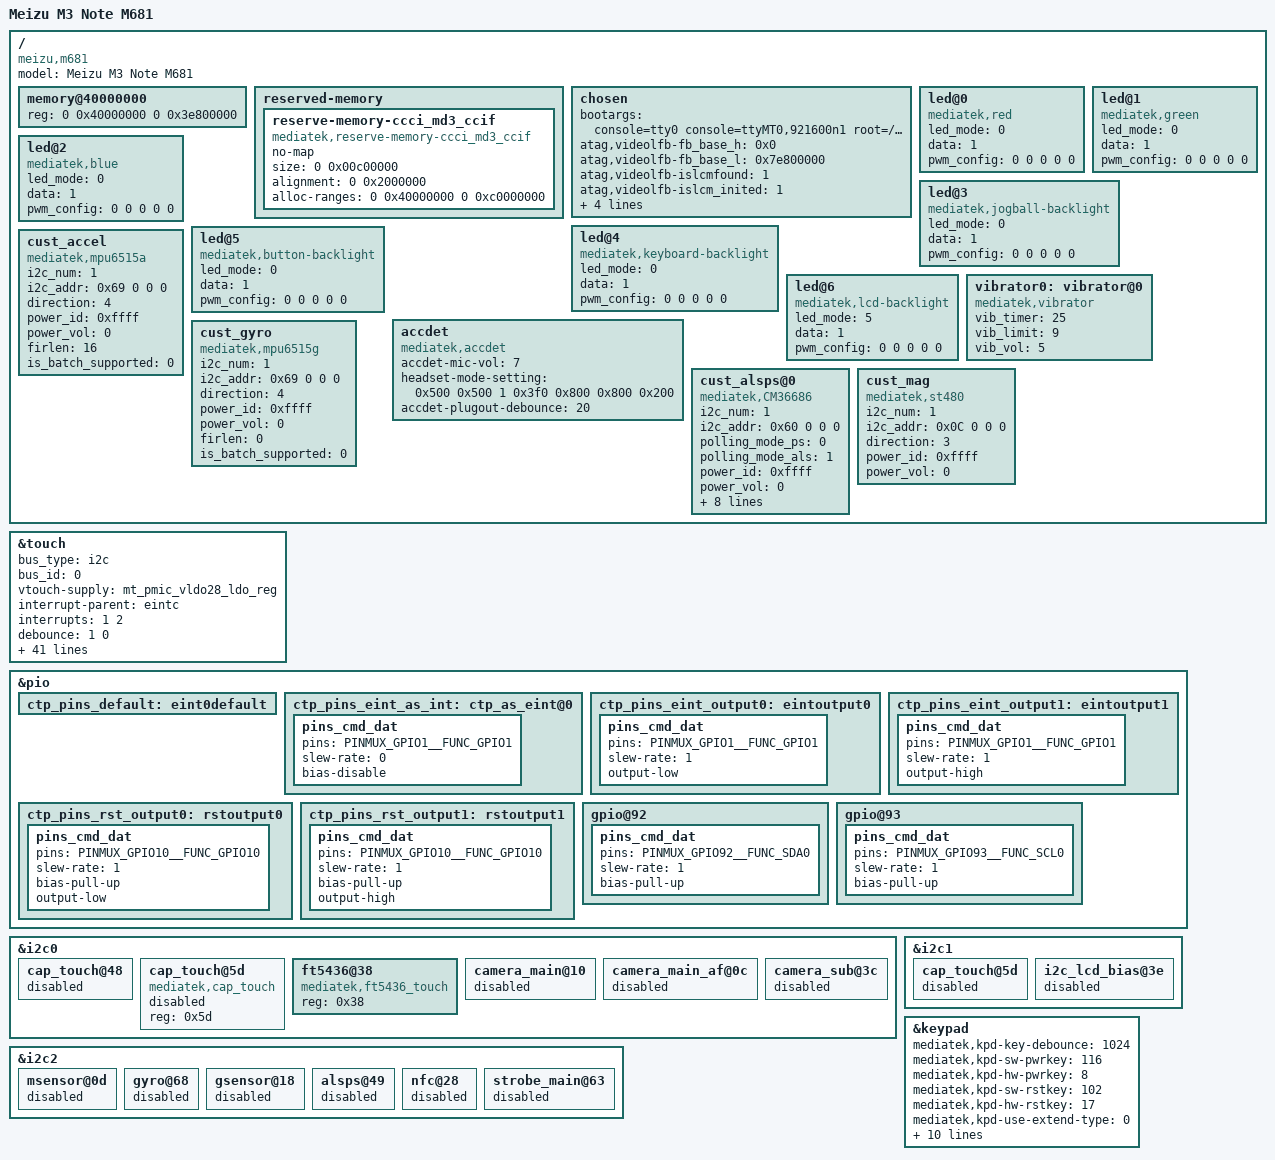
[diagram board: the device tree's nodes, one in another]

/dts-v1/;

#include "mt6755.dtsi"
#include "cust.dtsi"

/ {
	model = "Meizu M3 Note M681";
	compatible = "meizu,m681", "mediatek,mt6755";

	memory@40000000 {
		device_type = "memory";
		reg = <0 0x40000000 0 0x3e800000>;
	};

	reserved-memory {
		#address-cells = <2>;
		#size-cells = <2>;
		ranges;

		reserve-memory-ccci_md3_ccif {
			compatible = "mediatek,reserve-memory-ccci_md3_ccif";
			no-map;
			size = <0 0x00c00000>;
			alignment = <0 0x2000000>;
			alloc-ranges = <0 0x40000000 0 0xc0000000>;
		};
	};

	/* chosen */
	chosen {
		bootargs = "console=tty0 console=ttyMT0,921600n1 root=/dev/ram initrd=0x44000000,0x4b434e loglevel=4 printk.disable_uart=1 maxcpus=1 clk_ignore_unused";

		/* Real M681 boots through LK, so keep the fallback in sync with LK handoff. */
		/* fb buffer is reserved using this dts by memory node above */
		atag,videolfb-fb_base_h = <0x0>;
		atag,videolfb-fb_base_l = <0x7e800000>;
		atag,videolfb-islcmfound = <1>;
		atag,videolfb-islcm_inited = <1>;
		atag,videolfb-fps= <5716>;
		atag,videolfb-vramSize= <0x01be0000>;
		atag,videolfb-lcmname= "ili9885_fhd_dsi_vdo_txd1";
	};
	led@0 {
		compatible = "mediatek,red";
		led_mode = <0>;
		data = <1>;
		pwm_config = <0 0 0 0 0>;
	};
	led@1 {
		compatible = "mediatek,green";
		led_mode = <0>;
		data = <1>;
		pwm_config = <0 0 0 0 0>;
	};
	led@2 {
		compatible = "mediatek,blue";
		led_mode = <0>;
		data = <1>;
		pwm_config = <0 0 0 0 0>;
	};
	led@3 {
		compatible = "mediatek,jogball-backlight";
		led_mode = <0>;
		data = <1>;
		pwm_config = <0 0 0 0 0>;
	};
	led@4 {
		compatible = "mediatek,keyboard-backlight";
		led_mode = <0>;
		data = <1>;
		pwm_config = <0 0 0 0 0>;
	};
	led@5 {
		compatible = "mediatek,button-backlight";
		led_mode = <0>;
		data = <1>;
		pwm_config = <0 0 0 0 0>;
	};
	led@6 {
		compatible = "mediatek,lcd-backlight";
		/* v239h12-stock: CUST_BLS_PWM (was <7> = out-of-range -> MODE_NONE -> BL never blanked) */
		led_mode = <5>;
		data = <1>;
		pwm_config = <0 0 0 0 0>;
	};
	vibrator0:vibrator@0 {
		compatible = "mediatek,vibrator";
		vib_timer = <25>;
		vib_limit = <9>;
		vib_vol= <5>;
	};
	accdet {
		compatible = "mediatek,accdet";
		accdet-mic-vol = <7>;
		headset-mode-setting = <0x500 0x500 1 0x3f0 0x800 0x800 0x200>;
		accdet-plugout-debounce = <20>;
	};
/*  start sensor */
	/* m681 (wt6755_66_sz_l stock) sensors. alsps=CM36686, accel+gyro=MPU6515,
	 * mag=ST480, all on i2c bus 1. Chip + i2c_addr + direction taken from the
	 * stock m3note cust_acc.c/cust_gyro.c/cust_mag.c. compatible strings match
	 * the 3.18 driver get_*_dts_func() name lookups. */
	cust_accel {
		compatible = "mediatek,mpu6515a";
		i2c_num = <1>;
		i2c_addr = <0x69 0 0 0>;
		direction = <4>;
		power_id = <0xffff>;
		power_vol = <0>;
		firlen = <16>;
		is_batch_supported = <0>;
	};
	cust_gyro {
		compatible = "mediatek,mpu6515g";
		i2c_num = <1>;
		i2c_addr = <0x69 0 0 0>;
		direction = <4>;
		power_id = <0xffff>;
		power_vol = <0>;
		firlen = <0>;
		is_batch_supported = <0>;
	};
	cust_alsps@0 {
		compatible 				= "mediatek,CM36686";
		i2c_num 				= <1>;
		i2c_addr 				= <0x60 0 0 0>;
		polling_mode_ps			= <0>;
		polling_mode_als		= <1>;
		power_id   				= <0xffff>;
		power_vol  				= <0>;
		/* Total has 15 level*/
		als_level  				= <0 257 637 1027 2297 5588 6730 11301 20449 25768 31122 45552 57937 57937 57937>;
		/*  Total has 16 range*/
		als_value  				= <0 132 304 502 1004 2003 3006 5006 8004 10000 12000 16000 20000 20000 20000 20000>;
		ps_threshold_high		=  <70>;
		ps_threshold_low		=  <40>;
		is_batch_supported_ps	= <1>;
		is_batch_supported_als	= <1>;
	};
	cust_mag {
		compatible = "mediatek,st480";
		i2c_num = <1>;
		i2c_addr = <0x0C 0 0 0>;
		direction = <3>;
		power_id = <0xffff>;
		power_vol = <0>;
	};
/* end sensor */
};

/* TOUCH: INT=GPIO1, RST=GPIO10, vtouch=VLDO28, i2c0.
 * FT5436@0x38 confirmed via on-device i2c0 scan. */
&touch {
	bus_type = "i2c";
	bus_id = <0>;
	vtouch-supply = <&mt_pmic_vldo28_ldo_reg>;
	interrupt-parent = <&eintc>;
	interrupts = <1 2>;
	debounce = <1 0>;
	charger_supported = <1>;
	product = "Jim";
	slave_address = <93 72 0 0 0 0 0 0 0 0 0 0 0 0 0 0>;
	algo_id = <1>;
	hmx_irq_config = <3>;
	goodix_irq_config = <2>;
	need_wd_check_status = <1>;
	x_max = <720>;
	y_max = <1280>;
	x_max_mt = <720>;
	y_max_mt = <1280>;
	goodix,product_id = "GT917D";
	goodix,test-types = <0x80007>;
	goodix,panel-max = <3948>;
	goodix,panel-min = <1897>;
	goodix,panel-deviation = <400>;
	goodix,key-max = <0>;
	goodix,key-min = <0>;
	goodix,key-nc = <0>;
	goodix,special_raw_data_limit = <>;
	goodix,shortcircut-threshold = <0>;
	fw_upgrade_delay = <30000>;
	tpd-resolution = <1080 1920>;
	use-tpd-button = <0>;
	tpd-key-num = <3>;
	tpd-key-local= <139 172 158 0>;
	tpd-key-dim-local = <90 883 100 40 230 883 100 40 370 883 100 40 0 0 0 0>;
	tpd-max-touch-num = <5>;
	tpd-filter-enable = <1>;
	tpd-filter-pixel-density = <146>;
	tpd-filter-custom-prameters = <0 0 0 0 0 0 0 0 0 0 0 0>;
	tpd-filter-custom-speed = <0 0 0>;
	pinctrl-names = "default", "state_eint_as_int", "state_eint_output0", "state_eint_output1",
		"state_rst_output0", "state_rst_output1";
	pinctrl-0 = <&ctp_pins_default>;
	pinctrl-1 = <&ctp_pins_eint_as_int>;
	pinctrl-2 = <&ctp_pins_eint_output0>;
	pinctrl-3 = <&ctp_pins_eint_output1>;
	pinctrl-4 = <&ctp_pins_rst_output0>;
	pinctrl-5 = <&ctp_pins_rst_output1>;
	status = "okay";
};
&pio {
	ctp_pins_default: eint0default {
	};
	ctp_pins_eint_as_int: ctp_as_eint@0 {
		pins_cmd_dat {
			pins = <PINMUX_GPIO1__FUNC_GPIO1>;
			slew-rate = <0>;
			bias-disable;
		};
	};
	ctp_pins_eint_output0: eintoutput0 {
		pins_cmd_dat {
			pins = <PINMUX_GPIO1__FUNC_GPIO1>;
			slew-rate = <1>;
			output-low;
		};
	};
	ctp_pins_eint_output1: eintoutput1 {
		pins_cmd_dat {
			pins = <PINMUX_GPIO1__FUNC_GPIO1>;
			slew-rate = <1>;
			output-high;
		};
	};
	ctp_pins_rst_output0: rstoutput0 {
		pins_cmd_dat {
			pins = <PINMUX_GPIO10__FUNC_GPIO10>;
			slew-rate = <1>;
			bias-pull-up;
			output-low;
		};
	};
	ctp_pins_rst_output1: rstoutput1 {
		pins_cmd_dat {
			pins = <PINMUX_GPIO10__FUNC_GPIO10>;
			slew-rate = <1>;
			bias-pull-up;
			output-high;
		};
	};
	/* v239h12-stock: i2c0 SDA0/SCL0 pinmux — stock wt6755_66_sz_l cust_gpio.dtsi
	 * configures GPIO92=SDA0, GPIO93=SCL0 (mode 1). The graft DTS left these
	 * in GPIO mode (0) so the i2c0 controller clocked into a void (0 ACKs).
	 * Add explicit sub nodes here so the DTC pinctrl layer records the pad
	 * function; the focaltech driver ALSO calls mt_set_gpio_mode(92/93,1)
	 * directly as a belt+suspenders (the graft pinctrl layer was proven to
	 * drop &pio sub-nodes in prior sessions). */
	gpio@92 {
		pins_cmd_dat {
			pins = <PINMUX_GPIO92__FUNC_SDA0>;
			slew-rate = <1>;
			bias-pull-up;
		};
	};
	gpio@93 {
		pins_cmd_dat {
			pins = <PINMUX_GPIO93__FUNC_SCL0>;
			slew-rate = <1>;
			bias-pull-up;
		};
	};
};

&i2c0 {
	cap_touch@48 { status = "disabled"; };
	cap_touch@5d {
		compatible = "mediatek,cap_touch";
		reg = <0x5d>;
		status = "disabled";
	};
	ft5436@38 {
		compatible = "mediatek,ft5436_touch";
		reg = <0x38>;
		status = "okay";
	};
	camera_main@10 { status = "disabled"; };
	camera_main_af@0c { status = "disabled"; };
	camera_sub@3c { status = "disabled"; };
};
&i2c1 {
	cap_touch@5d { status = "disabled"; };
	i2c_lcd_bias@3e { status = "disabled"; };
};
&i2c2 {
	msensor@0d { status = "disabled"; };
	gyro@68 { status = "disabled"; };
	gsensor@18 { status = "disabled"; };
	alsps@49 { status = "disabled"; };
	nfc@28 { status = "disabled"; };
	strobe_main@63 { status = "disabled"; };
};

/* v239h12-stock: keypad override — align with stock wt6755_66_sz_l DCT
 * (cust_kpd.dtsi). The graft cust.dtsi (lines 223-241) had
 * kpd-hw-init-map = <114 0 ...> (only VOLDOWN at matrix pos0; VOLUP via
 * rstkey=115) AND kpd-sw-rstkey=115 (=VOLUP). Stock uses matrix pos0=VOLDOWN,
 * pos1=VOLUP and rstkey=HOME(102), so both VOLUP and HOME map correctly.
 * kpd driver reads mediatek,kpd-* from this node directly. The [FORGE_KPD]
 * probe markers in kpd.c (DIAGNOSTIC) confirm this reaches the driver. */
&keypad {
	mediatek,kpd-key-debounce = <1024>;
	mediatek,kpd-sw-pwrkey = <116>;
	mediatek,kpd-hw-pwrkey = <8>;
	mediatek,kpd-sw-rstkey = <102>;
	mediatek,kpd-hw-rstkey = <17>;
	mediatek,kpd-use-extend-type = <0>;
	mediatek,kpd-hw-map-num = <72>;
	mediatek,kpd-hw-init-map = <114 115 0 0 0 0 0 0 0 0 0 0 0 0 0 0 0 0 0 0 0 0 0 0 0 0 0 0 0 0 0 0 0 0 0 0 0 0 0 0 0 0 0 0 0 0 0 0 0 0 0 0 0 0 0 0 0 0 0 0 0 0 0 0 0 0 0 0 0 0 0 0>;
	mediatek,kpd-pwrkey-eint-gpio = <0>;
	mediatek,kpd-pwrkey-gpio-din = <0>;
	mediatek,kpd-hw-dl-key0 = <1>;
	mediatek,kpd-hw-dl-key1 = <0>;
	mediatek,kpd-hw-dl-key2 = <8>;
	mediatek,kpd-hw-recovery-key = <1>;
	mediatek,kpd-hw-factory-key = <0>;
};
